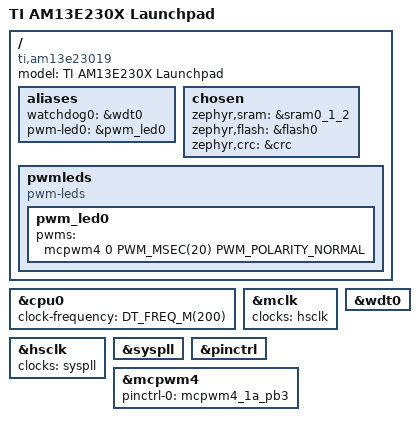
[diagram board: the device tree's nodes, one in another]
/*
 * Copyright (c) 2026 Texas Instruments Incorporated
 *
 * SPDX-License-Identifier: Apache-2.0
 */

/dts-v1/;

#include <ti/am13/am13e23019.dtsi>
#include <ti/am13/am13e23019-pinctrl.dtsi>
#include <zephyr/dt-bindings/pwm/pwm.h>

/ {
	compatible = "ti,am13e23019";
	model = "TI AM13E230X Launchpad";

	aliases {
		watchdog0 = &wdt0;
		pwm-led0 = &pwm_led0;
	};

	chosen {
		zephyr,sram = &sram0_1_2;
		zephyr,flash = &flash0;
		zephyr,crc = &crc;
	};

	pwmleds {
		compatible = "pwm-leds";

		pwm_led0: pwm_led0 {
			/* MCPWM4_1A on PB3 — B2SALEAE J4 pin 40 / Saleae ch0 */
			pwms = <&mcpwm4 0 PWM_MSEC(20) PWM_POLARITY_NORMAL>;
		};
	};
};

&cpu0 {
	clock-frequency = <DT_FREQ_M(200)>;
};

&mclk {
	clocks = <&hsclk>;
};

&hsclk {
	clocks = <&syspll>;
	status = "okay";
};

&syspll {
	status = "okay";
};

&wdt0 {
	status = "okay";
};

&pinctrl {
	status = "okay";
};

&mcpwm4 {
	pinctrl-0 = <&mcpwm4_1a_pb3>;
	pinctrl-names = "default";
	status = "okay";
};
